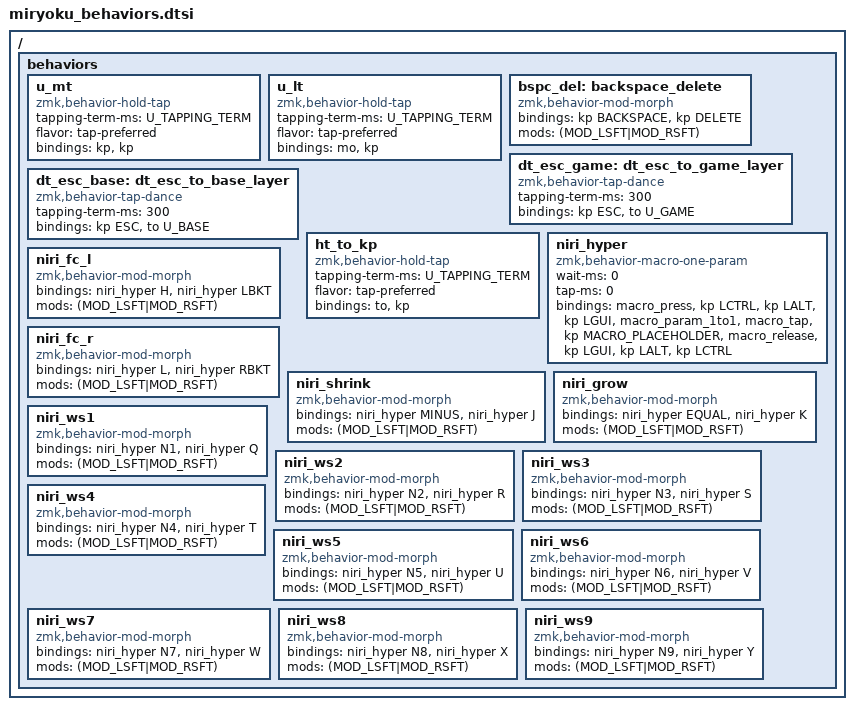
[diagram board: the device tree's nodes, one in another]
// Copyright 2022 Manna Harbour
// https://github.com/manna-harbour/miryoku

/ {
  behaviors {
    u_mt: u_mt {
      compatible = "zmk,behavior-hold-tap";
      #binding-cells = <2>;
      tapping-term-ms = <U_TAPPING_TERM>;
      flavor = "tap-preferred";
      bindings = <&kp>, <&kp>;
    };
    u_lt: u_lt {
      compatible = "zmk,behavior-hold-tap";
      #binding-cells = <2>;
      tapping-term-ms = <U_TAPPING_TERM>;
      flavor = "tap-preferred";
      bindings = <&mo>, <&kp>;
    };
    bspc_del: backspace_delete {
      compatible = "zmk,behavior-mod-morph";
      #binding-cells = <0>;
      bindings = <&kp BACKSPACE>, <&kp DELETE>;
      mods = <(MOD_LSFT|MOD_RSFT)>;
    };
    dt_esc_game: dt_esc_to_game_layer {
      compatible = "zmk,behavior-tap-dance";
      #binding-cells = <0>;
      tapping-term-ms = <300>;
      bindings = <&kp ESC>, <&to U_GAME>;
    };
    dt_esc_base: dt_esc_to_base_layer {
      compatible = "zmk,behavior-tap-dance";
      #binding-cells = <0>;
      tapping-term-ms = <300>;
      bindings = <&kp ESC>, <&to U_BASE>;
    };
    ht_to_kp: ht_to_kp {
      compatible = "zmk,behavior-hold-tap";
      #binding-cells = <2>;
      tapping-term-ms = <U_TAPPING_TERM>;
      flavor = "tap-preferred";
      bindings = <&to>, <&kp>;
    };

    niri_hyper: niri_hyper {
      compatible = "zmk,behavior-macro-one-param";
      #binding-cells = <1>;
      wait-ms = <0>;
      tap-ms = <0>;
      bindings
        = <&macro_press &kp LCTRL &kp LALT &kp LGUI>
        , <&macro_param_1to1>
        , <&macro_tap &kp MACRO_PLACEHOLDER>
        , <&macro_release &kp LGUI &kp LALT &kp LCTRL>;
    };

    niri_fc_l: niri_fc_l {
      compatible = "zmk,behavior-mod-morph";
      #binding-cells = <0>;
      bindings = <&niri_hyper H>, <&niri_hyper LBKT>;
      mods = <(MOD_LSFT|MOD_RSFT)>;
    };
    niri_fc_r: niri_fc_r {
      compatible = "zmk,behavior-mod-morph";
      #binding-cells = <0>;
      bindings = <&niri_hyper L>, <&niri_hyper RBKT>;
      mods = <(MOD_LSFT|MOD_RSFT)>;
    };
    niri_shrink: niri_shrink {
      compatible = "zmk,behavior-mod-morph";
      #binding-cells = <0>;
      bindings = <&niri_hyper MINUS>, <&niri_hyper J>;
      mods = <(MOD_LSFT|MOD_RSFT)>;
    };
    niri_grow: niri_grow {
      compatible = "zmk,behavior-mod-morph";
      #binding-cells = <0>;
      bindings = <&niri_hyper EQUAL>, <&niri_hyper K>;
      mods = <(MOD_LSFT|MOD_RSFT)>;
    };

    niri_ws1: niri_ws1 {
      compatible = "zmk,behavior-mod-morph";
      #binding-cells = <0>;
      bindings = <&niri_hyper N1>, <&niri_hyper Q>;
      mods = <(MOD_LSFT|MOD_RSFT)>;
    };
    niri_ws2: niri_ws2 {
      compatible = "zmk,behavior-mod-morph";
      #binding-cells = <0>;
      bindings = <&niri_hyper N2>, <&niri_hyper R>;
      mods = <(MOD_LSFT|MOD_RSFT)>;
    };
    niri_ws3: niri_ws3 {
      compatible = "zmk,behavior-mod-morph";
      #binding-cells = <0>;
      bindings = <&niri_hyper N3>, <&niri_hyper S>;
      mods = <(MOD_LSFT|MOD_RSFT)>;
    };
    niri_ws4: niri_ws4 {
      compatible = "zmk,behavior-mod-morph";
      #binding-cells = <0>;
      bindings = <&niri_hyper N4>, <&niri_hyper T>;
      mods = <(MOD_LSFT|MOD_RSFT)>;
    };
    niri_ws5: niri_ws5 {
      compatible = "zmk,behavior-mod-morph";
      #binding-cells = <0>;
      bindings = <&niri_hyper N5>, <&niri_hyper U>;
      mods = <(MOD_LSFT|MOD_RSFT)>;
    };
    niri_ws6: niri_ws6 {
      compatible = "zmk,behavior-mod-morph";
      #binding-cells = <0>;
      bindings = <&niri_hyper N6>, <&niri_hyper V>;
      mods = <(MOD_LSFT|MOD_RSFT)>;
    };
    niri_ws7: niri_ws7 {
      compatible = "zmk,behavior-mod-morph";
      #binding-cells = <0>;
      bindings = <&niri_hyper N7>, <&niri_hyper W>;
      mods = <(MOD_LSFT|MOD_RSFT)>;
    };
    niri_ws8: niri_ws8 {
      compatible = "zmk,behavior-mod-morph";
      #binding-cells = <0>;
      bindings = <&niri_hyper N8>, <&niri_hyper X>;
      mods = <(MOD_LSFT|MOD_RSFT)>;
    };
    niri_ws9: niri_ws9 {
      compatible = "zmk,behavior-mod-morph";
      #binding-cells = <0>;
      bindings = <&niri_hyper N9>, <&niri_hyper Y>;
      mods = <(MOD_LSFT|MOD_RSFT)>;
    };
  };
};
